# ESP32-C61 register map
Vendor: ESPRESSIF SYSTEMS (SHANGHAI) CO., LTD.; Series: ESP32 C-Series; File version: 1
CPU: RV32IMAC r0p0, little endian, no MPU, no FPU, 0 interrupt priority bits
Address unit: 32 bits
Registers are 32-bit, read-write, reset 0x0 unless marked. A register's access mark holds for its fields unless they carry their own. Offsets are from the block's base; [hi:lo] are bit positions; {n}, {i} and the like mark numbered series.

## SYSTIMER — System Timer
Base 0x6000A000
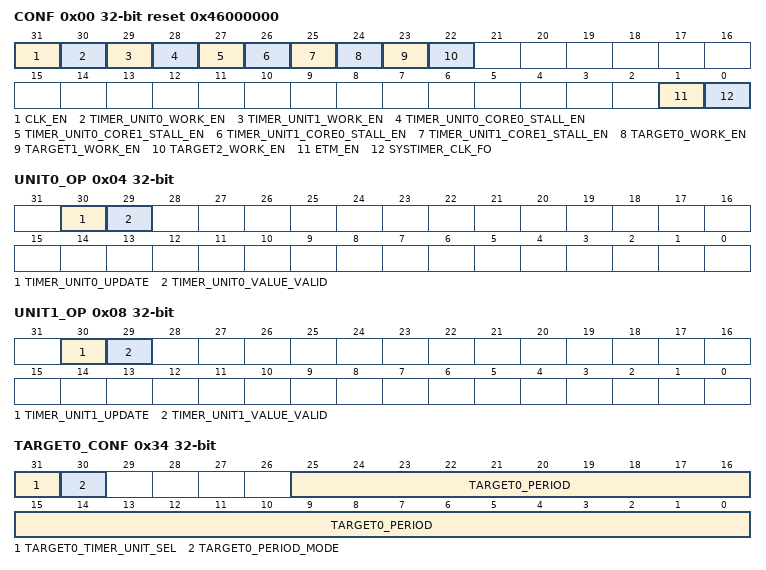
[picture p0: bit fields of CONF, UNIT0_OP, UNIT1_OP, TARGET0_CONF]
0x00 CONF reset 0x46000000 — Configure system timer clock
  [31] CLK_EN — Configures register clock gating. \\ 0: Only enable needed clock for register read or write operations. \\ 1: Register clock is always enabled for read and write operations. \\
  [30] TIMER_UNIT0_WORK_EN — Configures whether or not to enable UNIT0. \\ 0: Disable\\ 1: Enable\\
  [29] TIMER_UNIT1_WORK_EN — Configures whether or not to enable UNIT1. \\ 0: Disable\\ 1: Enable\\
  [28] TIMER_UNIT0_CORE0_STALL_EN — Configures whether or not UNIT0 is stalled when CORE0 is stalled. See details in SYSTIMER_TIMER_UNIT1_CORE1_STALL_EN.
  [27] TIMER_UNIT0_CORE1_STALL_EN — Configures whether or not UNIT0 is stalled when CORE1 is stalled. See details in SYSTIMER_TIMER_UNIT1_CORE1_STALL_EN.
  [26] TIMER_UNIT1_CORE0_STALL_EN — Configures whether or not UNIT1 is stalled when CORE0 is stalled. See details in SYSTIMER_TIMER_UNIT1_CORE1_STALL_EN.
  [25] TIMER_UNIT1_CORE1_STALL_EN — Configures whether or not UNIT1 is stalled when CORE1 is stalled. \\ 0: UNIT1 is not stalled. \\ 1: UNIT1 is stalled.\\
  [24] TARGET0_WORK_EN — Configures whether or not to enable COMP0. See details in SYSTIMER_TARGET2_WORK_EN.
  [23] TARGET1_WORK_EN — Configures whether or not to enable COMP1. See details in SYSTIMER_TARGET2_WORK_EN.
  [22] TARGET2_WORK_EN — Configures whether or not to enable COMP2.\\ 0: Disable\\ 1: Enable\\
  [1] ETM_EN — Configures whether or not to enable generation of ETM events.\\ 0: Disable\\ 1: Enable\\
  [0] SYSTIMER_CLK_FO — systimer clock force on
0x04 UNIT0_OP access per field — Read UNIT0 value to registers
  [30] TIMER_UNIT0_UPDATE wo — Configures whether or not to update timer UNIT0, i.e., reads the UNIT0 count value to SYSTIMER_TIMER_UNIT0_VALUE_HI and SYSTIMER_TIMER_UNIT0_VALUE_LO. \\ 0: No effect\\ 1: Update timer UNIT0 \\
  [29] TIMER_UNIT0_VALUE_VALID ro — Represents UNIT0 value is synchronized and valid.
0x08 UNIT1_OP access per field — Read UNIT1 value to registers
  [30] TIMER_UNIT1_UPDATE wo — Configures whether or not to update timer UNIT1, i.e., reads the UNIT1 count value to SYSTIMER_TIMER_UNIT1_VALUE_HI and SYSTIMER_TIMER_UNIT1_VALUE_LO. \\ 0: No effect \\ 1: Update timer UNIT1\\
  [29] TIMER_UNIT1_VALUE_VALID ro — Represents UNIT1 value is synchronized and valid.
0x0C UNIT0_LOAD_HI — High 20 bits to be loaded to UNIT0
  [19:0] TIMER_UNIT0_LOAD_HI — Configures the value to be loaded to UNIT0, high 20 bits.
0x10 UNIT0_LOAD_LO — Low 32 bits to be loaded to UNIT0
  [31:0] TIMER_UNIT0_LOAD_LO — Configures the value to be loaded to UNIT0, low 32 bits.
0x14 UNIT1_LOAD_HI — High 20 bits to be loaded to UNIT1
  [19:0] TIMER_UNIT1_LOAD_HI — Configures the value to be loaded to UNIT1, high 20 bits.
0x18 UNIT1_LOAD_LO — Low 32 bits to be loaded to UNIT1
  [31:0] TIMER_UNIT1_LOAD_LO — Configures the value to be loaded to UNIT1, low 32 bits.
{0x1C+8i} TARGET{i}_HI (i=0..2) — Alarm value to be loaded to COMP{i}, high 20 bits
  [19:0] TIMER_TARGET{i}_HI — Configures the alarm value to be loaded to COMP{i}, high 20 bits.
{0x20+8i} TARGET{i}_LO (i=0..2) — Alarm value to be loaded to COMP{i}, low 32 bits
  [31:0] TIMER_TARGET{i}_LO — Configures the alarm value to be loaded to COMP{i}, low 32 bits.
0x34 TARGET0_CONF — Configure COMP0 alarm mode
  [31] TARGET0_TIMER_UNIT_SEL — Chooses the counter value for comparison with COMP0.\\ 0: Use the count value from UNIT$0\\ 1: Use the count value from UNIT$1\\
  [30] TARGET0_PERIOD_MODE — Selects the two alarm modes for COMP0. \\ 0: Target mode\\ 1: Period mode\\
  [25:0] TARGET0_PERIOD — Configures COMP0 alarm period.
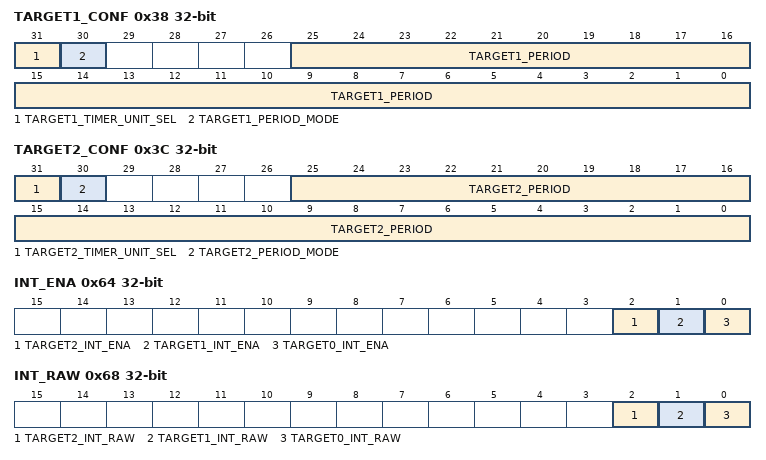
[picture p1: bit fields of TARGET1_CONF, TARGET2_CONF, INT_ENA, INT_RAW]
0x38 TARGET1_CONF — Configure COMP1 alarm mode
  [31] TARGET1_TIMER_UNIT_SEL — Chooses the counter value for comparison with COMP1. See details in SYSTIMER_TARGET0_TIMER_UNIT_SEL.
  [30] TARGET1_PERIOD_MODE — Selects the two alarm modes for COMP1. See details in SYSTIMER_TARGET0_PERIOD_MODE.
  [25:0] TARGET1_PERIOD — Configures COMP1 alarm period.
0x3C TARGET2_CONF — Configure COMP2 alarm mode
  [31] TARGET2_TIMER_UNIT_SEL — Chooses the counter value for comparison with COMP2. See details in SYSTIMER_TARGET0_TIMER_UNIT_SEL.
  [30] TARGET2_PERIOD_MODE — Configures Configures the two alarm modes for COMP2. See details in SYSTIMER_TARGET0_PERIOD_MODE.
  [25:0] TARGET2_PERIOD — Configures COMP2 alarm period.
0x40 UNIT0_VALUE_HI ro — UNIT0 value, high 20 bits
  [19:0] TIMER_UNIT0_VALUE_HI — Represents UNIT0 read value, high 20 bits.
0x44 UNIT0_VALUE_LO ro — UNIT0 value, low 32 bits
  [31:0] TIMER_UNIT0_VALUE_LO — Represents UNIT0 read value, low 32 bits.
0x48 UNIT1_VALUE_HI ro — UNIT1 value, high 20 bits
  [19:0] TIMER_UNIT1_VALUE_HI — Represents UNIT1 read value, high 20 bits.
0x4C UNIT1_VALUE_LO ro — UNIT1 value, low 32 bits
  [31:0] TIMER_UNIT1_VALUE_LO — Represents UNIT1 read value, low 32 bits.
0x50 COMP0_LOAD wo — COMP0 synchronization register
  [0] TIMER_COMP0_LOAD — Configures whether or not to enable COMP0 synchronization, i.e., reload the alarm value/period to COMP0.\\ 0: No effect \\ 1: Enable COMP0 synchronization\\
0x54 COMP1_LOAD wo — COMP1 synchronization register
  [0] TIMER_COMP1_LOAD — Configures whether or not to enable COMP1 synchronization, i.e., reload the alarm value/period to COMP1. \\ 0: No effect \\ 1: Enable COMP1 synchronization\\
0x58 COMP2_LOAD wo — COMP2 synchronization register
  [0] TIMER_COMP2_LOAD — Configures whether or not to enable COMP2 synchronization, i.e., reload the alarm value/period to COMP2.\\ 0: No effect \\ 1: Enable COMP2 synchronization\\
0x5C UNIT0_LOAD wo — UNIT0 synchronization register
  [0] TIMER_UNIT0_LOAD — Configures whether or not to reload the value of UNIT0, i.e., reloads the values of SYSTIMER_TIMER_UNIT0_VALUE_HI and SYSTIMER_TIMER_UNIT0_VALUE_LO to UNIT0. \\ 0: No effect \\ 1: Reload the value of UNIT0\\
0x60 UNIT1_LOAD wo — UNIT1 synchronization register
  [0] TIMER_UNIT1_LOAD — Configures whether or not to reload the value of UNIT1, i.e., reload the values of SYSTIMER_TIMER_UNIT1_VALUE_HI and SYSTIMER_TIMER_UNIT1_VALUE_LO to UNIT1. \\ 0: No effect \\ 1: Reload the value of UNIT1\\
0x64 INT_ENA — Interrupt enable register of system timer
  [2] TARGET2_INT_ENA — Write 1 to enable SYSTIMER_TARGET2_INT.
  [1] TARGET1_INT_ENA — Write 1 to enable SYSTIMER_TARGET1_INT.
  [0] TARGET0_INT_ENA — Write 1 to enable SYSTIMER_TARGET0_INT.
0x68 INT_RAW — Interrupt raw register of system timer
  [2] TARGET2_INT_RAW — The raw interrupt status of SYSTIMER_TARGET2_INT.
  [1] TARGET1_INT_RAW — The raw interrupt status of SYSTIMER_TARGET1_INT.
  [0] TARGET0_INT_RAW — The raw interrupt status of SYSTIMER_TARGET0_INT.
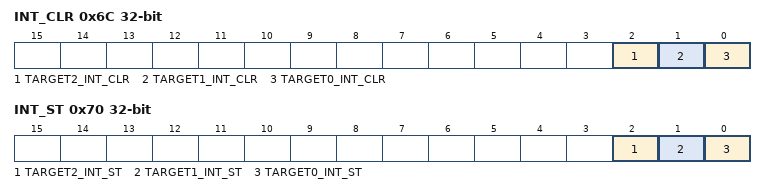
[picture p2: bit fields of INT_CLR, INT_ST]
0x6C INT_CLR wo — Interrupt clear register of system timer
  [2] TARGET2_INT_CLR — Write 1 to clear SYSTIMER_TARGET2_INT.
  [1] TARGET1_INT_CLR — Write 1 to clear SYSTIMER_TARGET1_INT.
  [0] TARGET0_INT_CLR — Write 1 to clear SYSTIMER_TARGET0_INT.
0x70 INT_ST ro — Interrupt status register of system timer
  [2] TARGET2_INT_ST — The interrupt status of SYSTIMER_TARGET2_INT.
  [1] TARGET1_INT_ST — The interrupt status of SYSTIMER_TARGET1_INT.
  [0] TARGET0_INT_ST — The interrupt status of SYSTIMER_TARGET0_INT.
{0x74+8i} REAL_TARGET{i}_LO ro (i=0..2) — Actual target value of COMP{i}, low 32 bits
  [31:0] TARGET{i}_LO_RO — Represents the actual target value of COMP{i}, low 32 bits.
{0x78+8i} REAL_TARGET{i}_HI ro (i=0..2) — Actual target value of COMP{i}, high 20 bits
  [19:0] TARGET{i}_HI_RO — Represents the actual target value of COMP{i}, high 20 bits.
0xFC DATE reset 0x2312220 — Version control register
  [31:0] DATE — Version control register.
